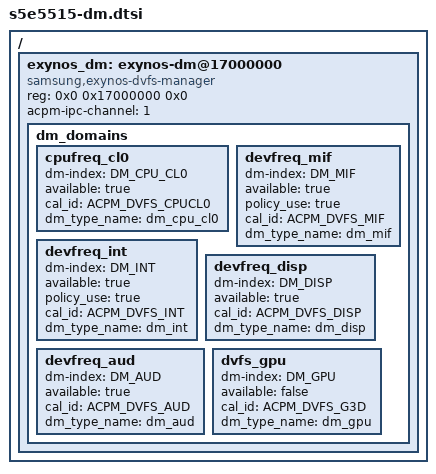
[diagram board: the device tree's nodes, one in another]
/*
* SAMSUNG EXYNOS5515 SoC ACPM device tree source
*
* Copyright (c) 2014 Samsung Electronics Co., Ltd.
*		http://www.samsung.com
*
* SAMSUNG EXYNOS5515 SoC device nodes are listed in this file.
* EXYNOS based board files can include this file and provide
* values for board specfic bindings.
*
* This program is free software; you can redistribute it and/or modify
* it under the terms of the GNU General Public License version 2 as
* published by the Free Software Foundation.
*/

#include <dt-bindings/soc/samsung/s5e5515-dm.h>

/ {
	exynos_dm: exynos-dm@17000000 {
		compatible = "samsung,exynos-dvfs-manager";
		reg = <0x0 0x17000000 0x0>;
		acpm-ipc-channel = <1>;
		dm_domains {
			cpufreq_cl0 {
				dm-index = <DM_CPU_CL0>;
				available = "true";
				cal_id = <ACPM_DVFS_CPUCL0>;
				dm_type_name = "dm_cpu_cl0";
			};
			devfreq_mif {
				dm-index = <DM_MIF>;
				available = "true";
				policy_use = "true";
				cal_id = <ACPM_DVFS_MIF>;
				dm_type_name = "dm_mif";
			};
			devfreq_int {
				dm-index = <DM_INT>;
				available = "true";
				policy_use = "true";
				cal_id = <ACPM_DVFS_INT>;
				dm_type_name = "dm_int";
			};
			devfreq_disp {
				dm-index = <DM_DISP>;
				available = "true";
				cal_id = <ACPM_DVFS_DISP>;
				dm_type_name = "dm_disp";
			};
			devfreq_aud {
				dm-index = <DM_AUD>;
				available = "true";
				cal_id = <ACPM_DVFS_AUD>;
				dm_type_name = "dm_aud";
			};
			dvfs_gpu {
				dm-index = <DM_GPU>;
				available = "false";
				cal_id = <ACPM_DVFS_G3D>;
				dm_type_name = "dm_gpu";
			};
		};
	};
};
